# STM32F415xx register map
File version: 1.0
Registers are 32-bit, read-write, reset 0x0 unless marked. A register's access mark holds for its fields unless they carry their own. Offsets are from the block's base; [hi:lo] are bit positions; {n}, {i} and the like mark numbered series.

## DMA1
Base 0x40026000
Same registers: DMA2 0x40026400
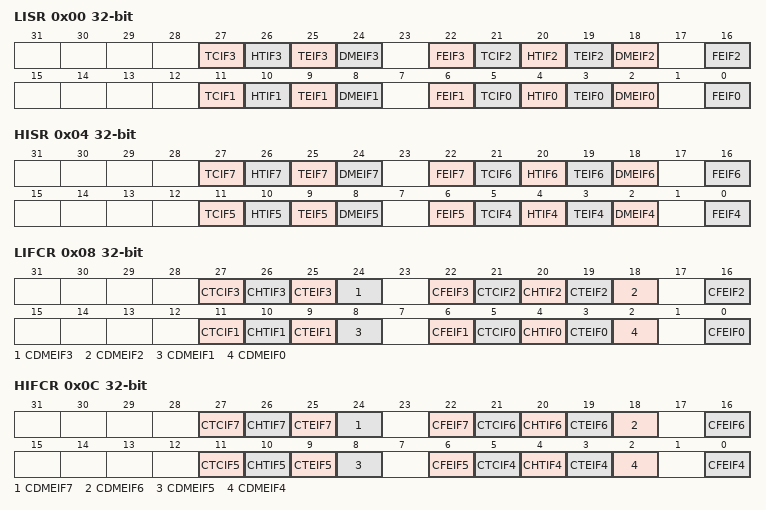
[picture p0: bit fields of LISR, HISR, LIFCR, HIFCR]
0x00 LISR — DMA low interrupt status register
  [27] TCIF3, [26] HTIF3, [25] TEIF3, [24] DMEIF3, [22] FEIF3, [21] TCIF2, [20] HTIF2, [19] TEIF2, [18] DMEIF2, [16] FEIF2, [11] TCIF1, [10] HTIF1, [9] TEIF1, [8] DMEIF1, [6] FEIF1, [5] TCIF0, [4] HTIF0, [3] TEIF0, [2] DMEIF0, [0] FEIF0
0x04 HISR — DMA high interrupt status register
  [27] TCIF7, [26] HTIF7, [25] TEIF7, [24] DMEIF7, [22] FEIF7, [21] TCIF6, [20] HTIF6, [19] TEIF6, [18] DMEIF6, [16] FEIF6, [11] TCIF5, [10] HTIF5, [9] TEIF5, [8] DMEIF5, [6] FEIF5, [5] TCIF4, [4] HTIF4, [3] TEIF4, [2] DMEIF4, [0] FEIF4
0x08 LIFCR — DMA low interrupt flag clear register
  [27] CTCIF3, [26] CHTIF3, [25] CTEIF3, [24] CDMEIF3, [22] CFEIF3, [21] CTCIF2, [20] CHTIF2, [19] CTEIF2, [18] CDMEIF2, [16] CFEIF2, [11] CTCIF1, [10] CHTIF1, [9] CTEIF1, [8] CDMEIF1, [6] CFEIF1, [5] CTCIF0, [4] CHTIF0, [3] CTEIF0, [2] CDMEIF0, [0] CFEIF0
0x0C HIFCR — DMA high interrupt flag clear register
  [27] CTCIF7, [26] CHTIF7, [25] CTEIF7, [24] CDMEIF7, [22] CFEIF7, [21] CTCIF6, [20] CHTIF6, [19] CTEIF6, [18] CDMEIF6, [16] CFEIF6, [11] CTCIF5, [10] CHTIF5, [9] CTEIF5, [8] CDMEIF5, [6] CFEIF5, [5] CTCIF4, [4] CHTIF4, [3] CTEIF4, [2] CDMEIF4, [0] CFEIF4
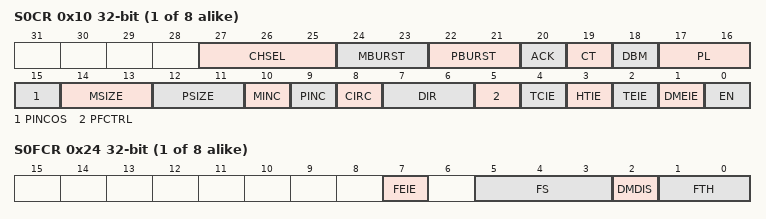
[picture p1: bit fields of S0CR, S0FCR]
{0x10+0x18*i} S{i}CR (i=0..7) — DMA stream x configuration register
  [27:25] CHSEL, [24:23] MBURST, [22:21] PBURST, [20] ACK, [19] CT, [18] DBM, [17:16] PL, [15] PINCOS, [14:13] MSIZE, [12:11] PSIZE, [10] MINC, [9] PINC, [8] CIRC, [7:6] DIR, [5] PFCTRL, [4] TCIE, [3] HTIE, [2] TEIE, [1] DMEIE, [0] EN
{0x14+0x18*i} S{i}NDTR (i=0..7) — DMA stream x number of data register
  [15:0] SxNDT
{0x18+0x18*i} S{i}PAR (i=0..7) — DMA stream x peripheral address register
  [31:0] PA — Peripheral Address
{0x1C+0x18*i} S{i}M0AR (i=0..7) — DMA stream x memory 0 address register
  [31:0] M0A — Memory Address
{0x20+0x18*i} S{i}M1AR (i=0..7) — DMA stream x memory 1 address register
  [31:0] M1A — Memory Address
{0x24+0x18*i} S{i}FCR (i=0..7) — DMA stream x FIFO control register
  [7] FEIE, [5:3] FS, [2] DMDIS, [1:0] FTH

## CRYP — Crypto Processor
Base 0x50060000
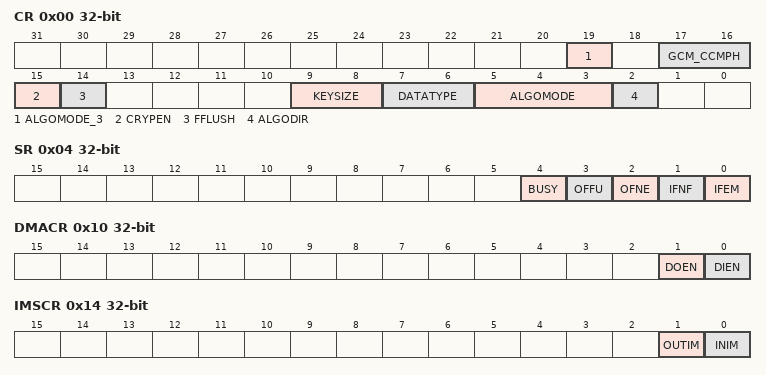
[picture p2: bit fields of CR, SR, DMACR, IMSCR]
0x00 CR — CRYP control register
  [19] ALGOMODE_3, [17:16] GCM_CCMPH, [15] CRYPEN, [14] FFLUSH, [9:8] KEYSIZE, [7:6] DATATYPE, [5:3] ALGOMODE, [2] ALGODIR
0x04 SR — CRYP status register
  [4] BUSY, [3] OFFU, [2] OFNE, [1] IFNF, [0] IFEM
0x08 DIN — CRYP data input register
0x0C DOUT — CRYP data output register
0x10 DMACR — CRYP DMA control register
  [1] DOEN, [0] DIEN
0x14 IMSCR — CRYP interrupt mask set/clear register
  [1] OUTIM, [0] INIM
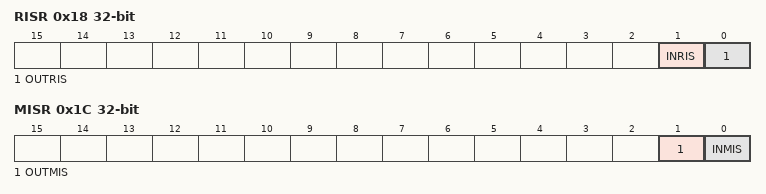
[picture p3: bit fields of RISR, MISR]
0x18 RISR — CRYP raw interrupt status register
  [1] INRIS, [0] OUTRIS
0x1C MISR — CRYP masked interrupt status register
  [1] OUTMIS, [0] INMIS
{0x20+8i} K{i}LR (i=0..3) — CRYP key left register {i}
{0x24+8i} K{i}RR (i=0..3) — CRYP key right register {i}
0x40 IV0LR — CRYP initialization vector left-word register 0
0x44 IV0RR — CRYP initialization vector right-word register 0
0x48 IV1LR — CRYP initialization vector left-word register 1
0x4C IV1RR — CRYP initialization vector right-word register 1
{0x50+4i} CSGCMCCM{i}R (i=0..7) — CRYP GCM/GMAC or CCM/CMAC context swap register {i}
{0x70+4i} CSGCM{i}R (i=0..7) — CRYP GCM/GMAC context swap register {i}

## HASH
Base 0x50060400
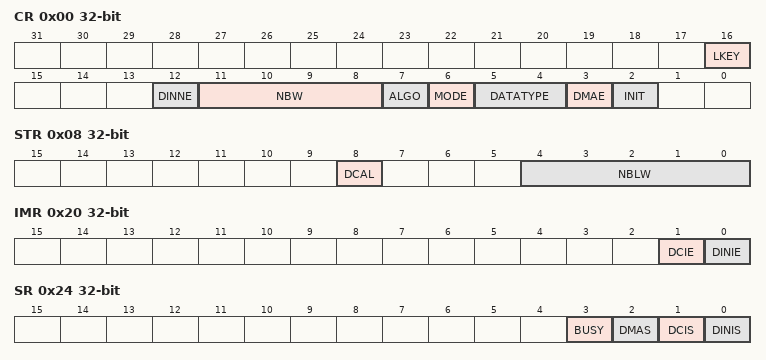
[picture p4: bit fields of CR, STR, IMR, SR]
0x00 CR — HASH control register
  [16] LKEY, [12] DINNE, [11:8] NBW, [7] ALGO, [6] MODE, [5:4] DATATYPE, [3] DMAE, [2] INIT
0x04 DIN — HASH data input register
0x08 STR — HASH start register
  [8] DCAL, [4:0] NBLW
{0xC+4i} HR{i} (i=0..4) — HASH digest registers
0x20 IMR — HASH interrupt enable register
  [1] DCIE, [0] DINIE
0x24 SR — HASH status register
  [3] BUSY, [2] DMAS, [1] DCIS, [0] DINIS
{0xF8+4i} CSR{i} (i=0..53) — HASH context swap registers
{0x310+4i} DIGEST_HR{i} (i=0..4) — HASH digest registers
